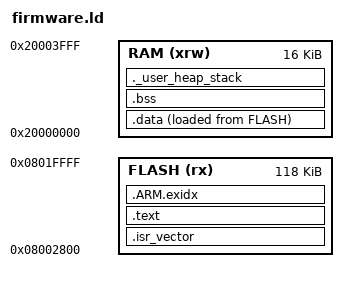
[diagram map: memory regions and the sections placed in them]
/* PY32F071xB (Quansheng UV-K5 V3 / UV-K1)
 * The factory bootloader occupies 0x08000000..0x080027FF and jumps to the
 * vector table at 0x08002800 (VTOR is set in SystemInit). */

ENTRY(Reset_Handler)

_estack = ORIGIN(RAM) + LENGTH(RAM);

_Min_Heap_Size  = 0;       /* required amount of heap  */
_Min_Stack_Size = 0x400;   /* required amount of stack */

MEMORY
{
	FLASH (rx)      : ORIGIN = 0x08002800, LENGTH = 118K
	RAM (xrw)       : ORIGIN = 0x20000000, LENGTH = 16K
}

SECTIONS
{
	.isr_vector :
	{
		. = ALIGN(4);
		KEEP(*(.isr_vector))
		. = ALIGN(4);
	} >FLASH

	.text :
	{
		. = ALIGN(4);
		*(.text)
		*(.text*)
		*(.rodata)
		*(.rodata*)
		*(.glue_7)
		*(.glue_7t)
		*(.eh_frame)

		KEEP(*(.init))
		KEEP(*(.fini))
		. = ALIGN(4);
		_etext = .;
	} >FLASH

	.ARM.exidx :
	{
		*(.ARM.exidx*)
	} >FLASH

	_sidata = LOADADDR(.data);

	.data :
	{
		. = ALIGN(4);
		_sdata = .;
		*(.data)
		*(.data*)
		. = ALIGN(4);
		_edata = .;
	} >RAM AT> FLASH

	. = ALIGN(4);
	.bss :
	{
		_sbss = .;
		__bss_start__ = _sbss;
		*(.bss)
		*(.bss*)
		*(COMMON)
		. = ALIGN(4);
		_ebss = .;
		__bss_end__ = _ebss;
	} >RAM

	._user_heap_stack :
	{
		. = ALIGN(8);
		PROVIDE(end = .);
		PROVIDE(_end = .);
		. = . + _Min_Heap_Size;
		. = . + _Min_Stack_Size;
		. = ALIGN(8);
	} >RAM

	.ARM.attributes 0 : { *(.ARM.attributes) }
}
